# GD32E53x register map
File version: 1.0
CPU: CM33 r0p4, little endian, MPU, FPU, 4 interrupt priority bits
Registers are 32-bit, read-write, reset 0x0 unless marked. A register's access mark holds for its fields unless they carry their own. Offsets are from the block's base; [hi:lo] are bit positions; {n}, {i} and the like mark numbered series.

## AFIO — Alternate-function I/Os
Base 0x40010000
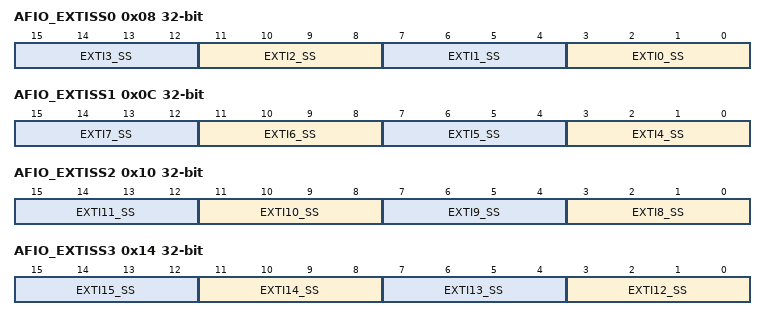
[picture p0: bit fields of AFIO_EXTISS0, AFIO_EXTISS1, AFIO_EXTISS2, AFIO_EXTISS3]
0x08 AFIO_EXTISS0 — EXTI sources selection register 0
  [4n+3:4n] EXTI{n}_SS (n=0..3) — EXTI {n} sources selection
0x0C AFIO_EXTISS1 — EXTI sources selection register 1
  [4n-13:4n-16] EXTI{n}_SS (n=4..7) — EXTI {n} sources selection
0x10 AFIO_EXTISS2 — EXTI sources selection register 2
  [4n-29:4n-32] EXTI{n}_SS (n=8..11) — EXTI {n} sources selection
0x14 AFIO_EXTISS3 — EXTI sources selection register 3
  [4n-45:4n-48] EXTI{n}_SS (n=12..15) — EXTI {n} sources selection
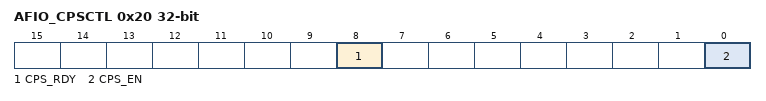
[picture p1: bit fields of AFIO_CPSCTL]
0x20 AFIO_CPSCTL access per field — IO compensation control register
  [8] CPS_RDY ro — I/O compensation cell is ready or not. This bit is read-only.
  [0] CPS_EN rw — I/O compensation cell enable.
0x24 AFIO_PD01 — PD01 remap register
  [0] PD01_REMAPEN — PD01 remapping register enable.

## CAU — Cryptographic Acceleration Unit
Base 0x40023400
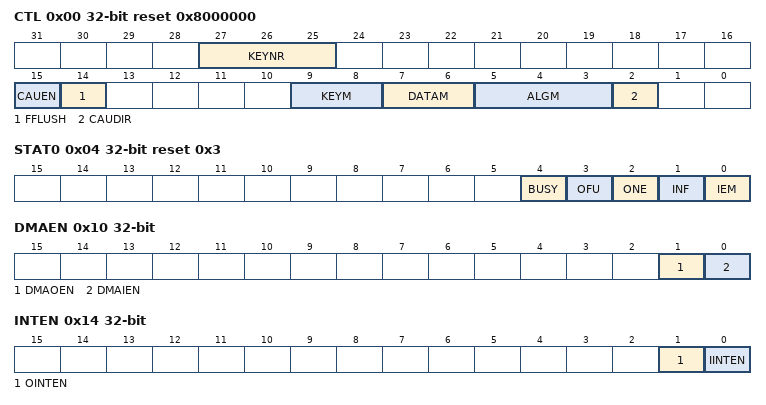
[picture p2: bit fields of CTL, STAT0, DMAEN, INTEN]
0x00 CTL access per field reset 0x8000000 — Control register
  [27:25] KEYNR rw — This bit field defines the number of the interal key for the selected operation.
  [15] CAUEN rw — CAU Enable
  [14] FFLUSH wo — Flush FIFO
  [9:8] KEYM rw — AES key size mode configuration, must be configured when BUSY=0
  [7:6] DATAM rw — Data swapping type mode configuration, must be configured when BUSY=0
  [5:3] ALGM rw — Encryption / decryption algorithm mode bit 0 to bit 2
  [2] CAUDIR rw — CAU direction, must be configured when BUSY=0
0x04 STAT0 ro reset 0x3 — Status register 0
  [4] BUSY — Busy bit
  [3] OFU — Output FIFO is full
  [2] ONE — Output FIFO is not empty
  [1] INF — Input FIFO is not full
  [0] IEM — Input FIFO is empty
0x08 DI — Data input register
  [31:0] DI — Data input
0x0C DO ro — Data output register
  [31:0] DO — Data output
0x10 DMAEN — DMA enable register
  [1] DMAOEN — DMA output enable
  [0] DMAIEN — DMA input enable
0x14 INTEN — Interrupt enable register
  [1] OINTEN — OUT FIFO interrupt enable
  [0] IINTEN — IN FIFO interrupt enable
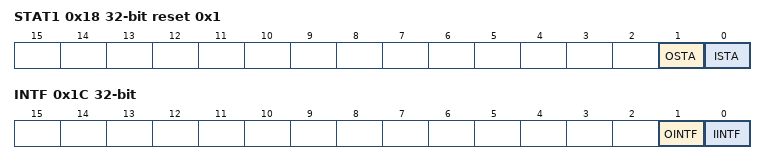
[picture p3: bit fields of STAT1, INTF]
0x18 STAT1 ro reset 0x1 — Status register 1
  [1] OSTA — OUT FIFO interrupt status
  [0] ISTA — IN FIFO interrupt status
0x1C INTF ro — Interrupt flag register
  [1] OINTF — OUT FIFO enabled interrupt flag
  [0] IINTF — IN FIFO enabled interrupt flag
{0x20+8i} KEY{i}H wo (i=0..3) — CAU key register
  [31:0] KEY{i}H — Key for DES,TDES,AES
{0x24+8i} KEY{i}L wo (i=0..3) — CAU key register
  [31:0] KEY{i}L — Key for DES,TDES,AES
0x100 ERROR_FLAG
  [0] FMC_KEY_ERROR_FLAG

## CMP — Comparator
Base 0x40017C00
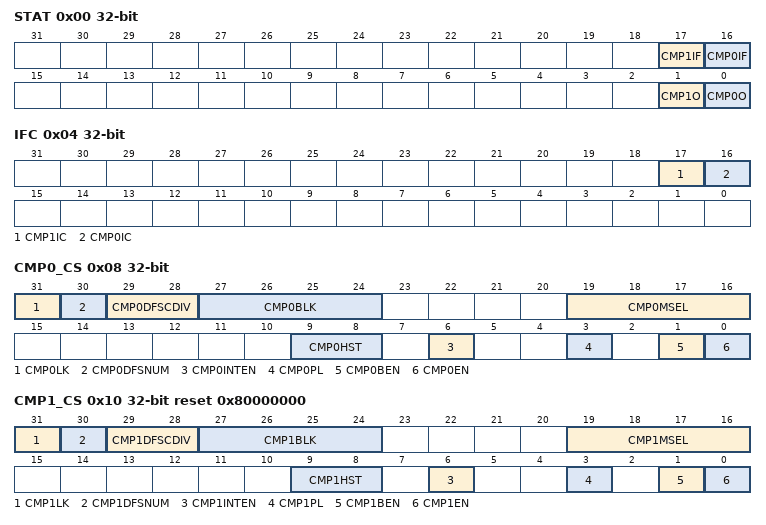
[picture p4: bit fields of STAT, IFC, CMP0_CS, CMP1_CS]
0x00 STAT ro — Status register
  [17] CMP1IF — CMP1 interrupt flag
  [16] CMP0IF — CMP0 interrupt flag
  [1] CMP1O — CMP1 output state
  [0] CMP0O — CMP0 output state
0x04 IFC wo — Interrupt flag clear register
  [17] CMP1IC — CMP1 interrupt flag clear
  [16] CMP0IC — CMP0 interrupt flag clear
0x08 CMP0_CS — CMP0 control/status register
  [31] CMP0LK — CMP0 lock
  [30] CMP0DFSNUM — Noise filter mode
  [29:28] CMP0DFSCDIV — CMP0 digital noise sampling selection.
  [27:24] CMP0BLK — CMP0 output blanking source
  [19:16] CMP0MSEL — CMP0_IM internal input selection
  [9:8] CMP0HST — CMP0 hysteresis
  [6] CMP0INTEN — CMP0 interrupt enable
  [3] CMP0PL — Polarity of CMP0 output
  [1] CMP0BEN — Scaler bridge enable bit
  [0] CMP0EN — CMP0 enable
0x10 CMP1_CS reset 0x80000000 — CMP1 control/status register
  [31] CMP1LK — CMP1 lock
  [30] CMP1DFSNUM — Noise filter mode
  [29:28] CMP1DFSCDIV — CMP1 digital noise sampling selection.
  [27:24] CMP1BLK — CMP1 output blanking source
  [19:16] CMP1MSEL — CMP1_IM internal input selection
  [9:8] CMP1HST — CMP1 hysteresis
  [6] CMP1INTEN — CMP1 interrupt enable
  [3] CMP1PL — Polarity of CMP1 output
  [1] CMP1BEN — Scaler bridge enable bit
  [0] CMP1EN — CMP1 enable
